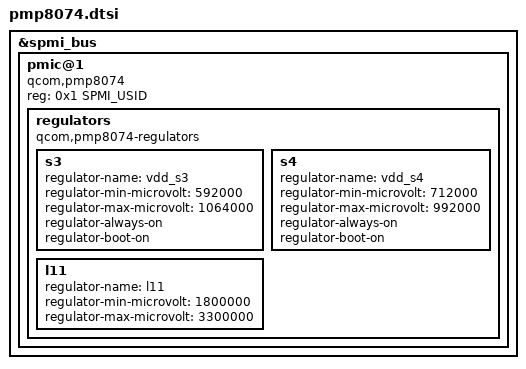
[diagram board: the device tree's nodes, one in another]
// SPDX-License-Identifier: GPL-2.0-only

#include <dt-bindings/spmi/spmi.h>

&spmi_bus {
	pmic@1 {
		compatible = "qcom,pmp8074", "qcom,spmi-pmic";
		reg = <0x1 SPMI_USID>;

		regulators {
			compatible = "qcom,pmp8074-regulators";

			s3: s3 {
				regulator-name = "vdd_s3";
				regulator-min-microvolt = <592000>;
				regulator-max-microvolt = <1064000>;
				regulator-always-on;
				regulator-boot-on;
			};

			s4: s4 {
				regulator-name = "vdd_s4";
				regulator-min-microvolt = <712000>;
				regulator-max-microvolt = <992000>;
				regulator-always-on;
				regulator-boot-on;
			};

			l11: l11 {
				regulator-name = "l11";
				regulator-min-microvolt = <1800000>;
				regulator-max-microvolt = <3300000>;
			};
		};
	};
};
